# SEC_MMR0_BOOT_CTRL register map
Vendor: Texas Instruments
Peripheral module from a debugger description file (folder J7VCL).
Registers are 32-bit, access per field, reset 0x0 unless marked. A register's access mark holds for its fields unless they carry their own. Offsets are as the file gives them; lines under a group give offsets from that group; [hi:lo] are bit positions; {n}, {i} and the like mark numbered series; 'fields as' and 'values as' point back to an identical list; <NAME> marks a mode.

## SEC_MMR0_BOOT_CTRL
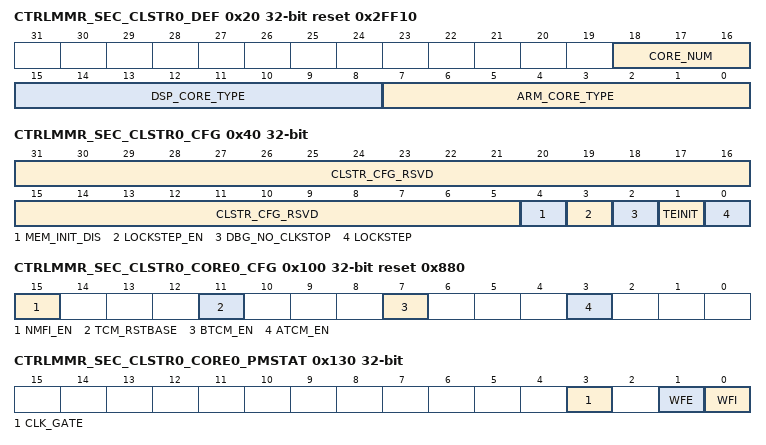
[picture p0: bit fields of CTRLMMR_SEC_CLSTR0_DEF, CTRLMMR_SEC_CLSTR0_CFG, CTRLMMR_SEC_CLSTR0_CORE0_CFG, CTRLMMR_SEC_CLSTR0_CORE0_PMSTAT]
0x20 CTRLMMR_SEC_CLSTR0_DEF ro reset 0x2FF10 — Defines the type of the processor cluster.
  [18:16] CORE_NUM — Number of cores in cluster
  [15:8] DSP_CORE_TYPE — DSP core type configuration 00h - C7x 01h - C6x FFh - Not DSP
  [7:0] ARM_CORE_TYPE — ARM core type configuration 00h - A53 01h - A57 10h - R5 FFh - Not ARM
0x40 CTRLMMR_SEC_CLSTR0_CFG (reset mask 0xFFFFFFF6) — Configures cluster level characteristics.
  [31:5] CLSTR_CFG_RSVD rw — Reserved for future use. Write '0' to ensure compatibility with future devices.
  [4] MEM_INIT_DIS rw — Disables SRAM initialization (TCM, Cache Tags, etc) at reset
  [3] LOCKSTEP_EN ro — Lockstep enable. Indicates if R5 lockstep operation is supported on the device
  [2] DBG_NO_CLKSTOP rw — CPU clockstop behavior
  [1] TEINIT rw — Exception handling state at reset:
  [0] LOCKSTEP rw — When set, Core0 and Core1 operate in lockstep mode. Can only be changed if lockstep operation is supported as indicated by CLSTR0_CFG_lockstep_en = 1. If CLSTR0_CFG_lockstep_en = 0, lockstep is not supported, this bit will be read only with a value of 0.
0x100 CTRLMMR_SEC_CLSTR0_CORE0_CFG reset 0x880 — Configures the TCM and interrupt operation of R5 Core0.
  [15] NMFI_EN rw — Enable Core0 Non-Maskable Fast Interrupts when set
  [11] TCM_RSTBASE rw — Core0 A/BTCM Reset Base Address Indicator
  [7] BTCM_EN rw — Enable Core0 BTCM RAM at reset when set
  [3] ATCM_EN rw — Enable Core0 ATCM RAM at reset when set
0x110 CTRLMMR_SEC_CLSTR0_CORE0_BOOTVECT_LO reset 0x200 — Contains the lower 32 bits of the boot vector location for R5 Core0. Bits 4:0 are not used and are always 0.
  [31:7] VECT_ADDR rw — Specifies the lower 25 bits of the 41-bit vector address corresponding to Vector Table address bits[31:7]. Note bits 6:0 of the Vector Table address are always 0.
0x114 CTRLMMR_SEC_CLSTR0_CORE0_BOOTVECT_HI — Contains the lower 16 bits of the boot vector location for R5 Core0.
  [15:0] VECT_ADDR rw — Specifies the upper 16 bits of the 41-bit vector address corresponding to Vector Table address bits[47:32].
0x120 CTRLMMR_SEC_CLSTR0_CORE0_PMCTRL — Configures Cluster Core0 power state.
  [0] CORE_HALT rw — Halt Core0.When 0, indicates that Core0 is in the Halt state.
0x130 CTRLMMR_SEC_CLSTR0_CORE0_PMSTAT ro (reset mask 0xFFFFFFF4) — Shows Cluster Core0 power status.
  [3] CLK_GATE — Core0 Clocked stoppedWhen 0, indicates clock stopped due to WFI or WFE state
  [1] WFE — Core0 WFE
  [0] WFI — Core0 WFI
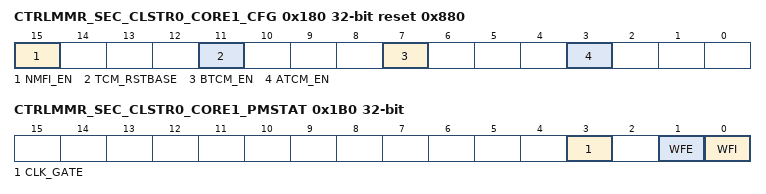
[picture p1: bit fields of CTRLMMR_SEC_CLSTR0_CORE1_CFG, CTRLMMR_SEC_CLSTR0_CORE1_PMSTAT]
0x180 CTRLMMR_SEC_CLSTR0_CORE1_CFG reset 0x880 — Configures the TCM and interrupt operation of R5 Core1.
  [15] NMFI_EN rw — Enable Core1 Non-Maskable Fast Interrupts when set
  [11] TCM_RSTBASE rw — Core1 A/BTCM Reset Base Address Indicator
  [7] BTCM_EN rw — Enable Core1 BTCM RAM at reset when set
  [3] ATCM_EN rw — Enable Core1 ATCM RAM at reset when set
0x190 CTRLMMR_SEC_CLSTR0_CORE1_BOOTVECT_LO reset 0x200 — Contains the lower 32 bits of the boot vector location for R5 Core1. Bits 4:0 are not used and are always 0.
  fields as CTRLMMR_SEC_CLSTR0_CORE0_BOOTVECT_LO
0x194 CTRLMMR_SEC_CLSTR0_CORE1_BOOTVECT_HI — Contains the lower 16 bits of the boot vector location for R5 Core1.
  fields as CTRLMMR_SEC_CLSTR0_CORE0_BOOTVECT_HI
0x1A0 CTRLMMR_SEC_CLSTR0_CORE1_PMCTRL — Configures Cluster Core1 power state.
  [0] CORE_HALT rw — Halt Core1.When 0, indicates that Core1 is in the Halt state.
0x1B0 CTRLMMR_SEC_CLSTR0_CORE1_PMSTAT ro (reset mask 0xFFFFFFF4) — Shows Cluster Core1 power status.
  [3] CLK_GATE — Core1 Clocked stoppedWhen 0, indicates clock stopped due to WFI or WFE state
  [1] WFE — Core1 WFE
  [0] WFI — Core1 WFI
